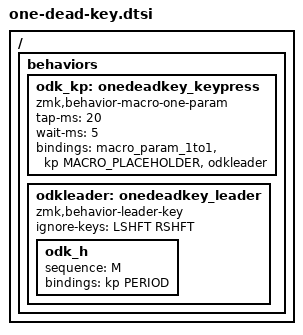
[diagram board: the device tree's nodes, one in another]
/ {
  behaviors {
    odk_kp: onedeadkey_keypress {
      compatible = "zmk,behavior-macro-one-param";
      #binding-cells = <1>;
      tap-ms = <20>;
      wait-ms = <5>;
      bindings = <&macro_param_1to1>, <&kp MACRO_PLACEHOLDER &odkleader>;
    };
    odkleader: onedeadkey_leader {
      compatible = "zmk,behavior-leader-key";
      #binding-cells = <0>;
      ignore-keys = <LSHFT RSHFT>;
      odk_h { sequence = <M>; bindings = <&kp PERIOD>; };
    };
  };
};
